# MM32F031x8 register map
Vendor: MindMotion Ltd.; Series: MM32F0; File version: 1.4
MindMotion 32-bit Cortex-M0 Microcontroller based device, CPU clock up to 96MHz, etc.
CPU: CM0 r0p0, little endian, no MPU, no FPU, 3 interrupt priority bits
Registers are 32-bit, read-write, reset 0x0 unless marked. A register's access mark holds for its fields unless they carry their own. Offsets are from the block's base; lines under a group give offsets from that group; [hi:lo] are bit positions; {n}, {i} and the like mark numbered series; 'fields as' and 'values as' point back to an identical list; <NAME> marks a mode.

## Memory map
0x40000000 TIM2 size 0x400 — General purpose timer
0x40000400 TIM3 size 0x400
0x40002C00 WWDG size 0x400 — Window watchdog
0x40003000 IWDG size 0x400 — Independent watchdog
0x40003800 SPI2 size 0x400
0x40004400 UART2 size 0x400
0x40005400 I2C1 size 0x400 — Inter integrated circuit
0x40005C00 USB size 0x400 — Universal serial bus full-speed device interface
0x40006400 CAN size 0x400 — Controller area network
0x40006C00 CRS size 0x400 — Clock Recovery System
0x40007000 PWR size 0x400 — Power control
0x40010000 SYSCFG size 0x400
0x40010400 EXTI size 0x400
0x40012400 ADC size 0x400 — Analog to digital converter
0x40012C00 TIM1 size 0x400 — Advanced timer
0x40013000 SPI1 size 0x400 — Serial peripheral interface
0x40013800 UART1 size 0x400 — Universal asynchronous receiver transmitter
0x40013C00 COMP size 0x400 — comparator
0x40014000 TIM14 size 0x400 — Advanced timer
0x40014400 TIM16 size 0x400 — Advanced timer
0x40014800 TIM17 size 0x400
0x40020000 DMA size 0x400 — DMA controller
0x40021000 RCC size 0x400 — Reset and clock control
0x40022000 FLASH size 0x400
0x48000000 GPIOA size 0x400 — General purpose I/O
0x48000400 GPIOB size 0x400
0x48000800 GPIOC size 0x400
0x48000C00 GPIOD size 0x400
0xE0042000 DBG size 0x400 — Debug support

## Interrupts
0 WWDG — Window Watchdog interrupt
1 PVD (PWR) — PVD through EXTI line detection interrupt
3 FLASH — Flash global interrupt
4 RCC — RCC global interrupt
5 EXTI0_1 (EXTI) — EXTI Line0 interrupt
6 EXTI2_3 (EXTI) — EXTI Line1 interrupt
7 EXTI4_15 (EXTI) — EXTI Line2 interrupt
9 DMA1_Channel1 (DMA) — DMA1 Channel2 global interrupt
10 DMA1_Channel2_3 (DMA) — DMA1 Channel3 global interrupt
11 DMA1_Channel4_5 (DMA) — DMA1 Channel4 global interrupt
12 ADC — ADC1 global interrupt
14 TIM1_CC (TIM1) — TIM1 Capture Compare interrupt
15 TIM2 — TIM2 global interrupt
16 TIM3 — TIM3 global interrupt
19 TIM14_0 (TIM14) — TIM14 global interrupt
21 TIM16 — TIM16 global interrupt
22 TIM17 — TIM17 global interrupt
23 I2C1_EV (I2C1) — I2C1 global interrupt
25 SPI1 — SPI1 global interrupt
26 SPI2 — SPI2 global interrupt
27 UART1 — UART1 global interrupt
28 UART2 — UART2 global interrupt
30 CAN1_TX (CAN) — CAN1 TX interrupts
42 USB_FS_WKUP (USB) — USB Device FS Wakeup through EXTI line interrupt

## FLASH
Base 0x40022000
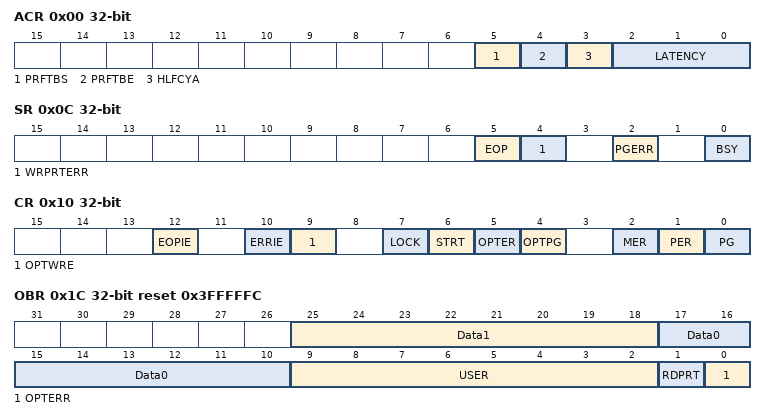
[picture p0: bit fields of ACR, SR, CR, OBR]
0x00 ACR
  [5] PRFTBS — Prefetch buffer status
  [4] PRFTBE — Prefetch buffer enable
  [3] HLFCYA — Flash half cycle access enable
  [2:0] LATENCY
0x04 KEYR wo
  [31:0] FKEYR — Flash key
0x08 OPTKEYR wo
  [31:0] OPTKEYR — Option byte key
0x0C SR
  [5] EOP — End of operation
  [4] WRPRTERR — Write protection error
  [2] PGERR — Programming error
  [0] BSY — Busy
0x10 CR
  [12] EOPIE — End of operation interrupt enable
  [10] ERRIE — Error interrupt enable
  [9] OPTWRE — Option byte write enable
  [7] LOCK
  [6] STRT — Start
  [5] OPTER — Option byte erase
  [4] OPTPG — Option byte programming
  [2] MER — Mass erase
  [1] PER — Page erase
  [0] PG — Programming
0x14 AR wo
  [31:0] FAR — Flash Address
0x1C OBR ro reset 0x3FFFFFC
  [25:18] Data1
  [17:10] Data0
  [9:2] USER — User option bytes
  [1] RDPRT — Read protection level status
  [0] OPTERR — Option byte error
0x20 WRPR ro reset 0xFFFFFFFF
  [31:0] WRP — Write protect

## PWR — Power control
Base 0x40007000
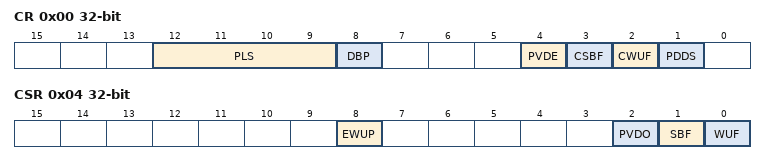
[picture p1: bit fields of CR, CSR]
0x00 CR
  [12:9] PLS — PVD level selection
  [8] DBP — domain write protection
  [4] PVDE — Power voltage detector enable
  [3] CSBF — Clear standby flag
  [2] CWUF — Clear wakeup flag
  [1] PDDS — Power down deepsleep
0x04 CSR
  [8] EWUP — Enable WKUP pin
  [2] PVDO — PVD output
  [1] SBF — Standby flag
  [0] WUF — Wakeup flag

## Licence text in the file
MindMotion Limited (MindMotion) is supplying this software for use with Cortex-M0!
